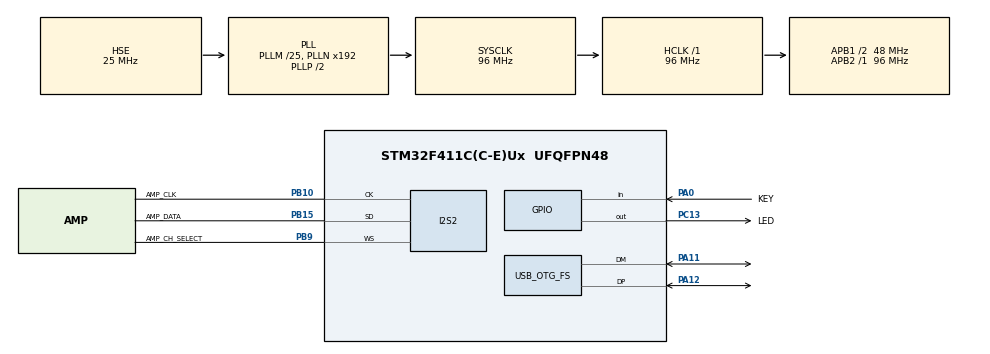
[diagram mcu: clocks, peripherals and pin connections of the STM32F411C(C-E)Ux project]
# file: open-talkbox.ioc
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Dma.Request0=SPI2_TX
Dma.SPI2_TX.0.Direction=DMA_MEMORY_TO_PERIPH
Dma.SPI2_TX.0.FIFOMode=DMA_FIFOMODE_DISABLE
Dma.SPI2_TX.0.Instance=DMA1_Stream4
Dma.SPI2_TX.0.MemDataAlignment=DMA_MDATAALIGN_HALFWORD
Dma.SPI2_TX.0.MemInc=DMA_MINC_ENABLE
Dma.SPI2_TX.0.Mode=DMA_CIRCULAR
Dma.SPI2_TX.0.PeriphDataAlignment=DMA_PDATAALIGN_HALFWORD
Dma.SPI2_TX.0.PeriphInc=DMA_PINC_DISABLE
Dma.SPI2_TX.0.Priority=DMA_PRIORITY_LOW
I2S2.AudioFreq=I2S_AUDIOFREQ_16K
I2S2.ErrorAudioFreq=-0.12 %
I2S2.FullDuplexMode=I2S_FULLDUPLEXMODE_DISABLE
I2S2.Instance=SPI$Index
I2S2.RealAudioFreq=15.98 KHz
I2S2.VirtualMode=I2S_MODE_MASTER
Mcu.Family=STM32F4
Mcu.Name=STM32F411C(C-E)Ux
Mcu.Package=UFQFPN48
NVIC.DMA1_Stream4_IRQn=true\:0\:0\:false\:false\:true\:false\:true
NVIC.OTG_FS_IRQn=true\:0\:0\:false\:false\:true\:false\:true
NVIC.PriorityGroup=NVIC_PRIORITYGROUP_4
PA0-WKUP.GPIO_Label=KEY
PA0-WKUP.GPIO_PuPd=GPIO_PULLUP
PA0-WKUP.Signal=GPIO_Input
PA11.Mode=Device_Only
PA11.Signal=USB_OTG_FS_DM
PA12.Mode=Device_Only
PA12.Signal=USB_OTG_FS_DP
PA13.Mode=Serial_Wire
PA13.Signal=SYS_JTMS-SWDIO
PA14.Mode=Serial_Wire
PA14.Signal=SYS_JTCK-SWCLK
PB10.GPIO_Label=AMP_CLK
PB10.Mode=Half_Duplex_Master
PB10.Signal=I2S2_CK
PB15.GPIO_Label=AMP_DATA
PB15.Mode=Half_Duplex_Master
PB15.Signal=I2S2_SD
PB9.GPIO_Label=AMP_CH_SELECT
PB9.Mode=Half_Duplex_Master
PB9.Signal=I2S2_WS
PC13-ANTI_TAMP.GPIO_Label=LED
PC13-ANTI_TAMP.Signal=GPIO_Output
PC14-OSC32_IN.Mode=LSE-External-Oscillator
PC14-OSC32_IN.Signal=RCC_OSC32_IN
PC15-OSC32_OUT.Mode=LSE-External-Oscillator
PC15-OSC32_OUT.Signal=RCC_OSC32_OUT
PH0\ -\ OSC_IN.Mode=HSE-External-Oscillator
PH0\ -\ OSC_IN.Signal=RCC_OSC_IN
PH1\ -\ OSC_OUT.Mode=HSE-External-Oscillator
PH1\ -\ OSC_OUT.Signal=RCC_OSC_OUT
ProjectManager.HeapSize=0x200
ProjectManager.StackSize=0x400
ProjectManager.TargetToolchain=STM32CubeIDE
RCC.48MHZClocksFreq_Value=48000000
RCC.AHBFreq_Value=96000000
RCC.APB1CLKDivider=RCC_HCLK_DIV2
RCC.APB1Freq_Value=48000000
RCC.APB1TimFreq_Value=96000000
RCC.APB2Freq_Value=96000000
RCC.APB2TimFreq_Value=96000000
RCC.CortexFreq_Value=96000000
RCC.HCLKFreq_Value=96000000
RCC.HSE_VALUE=25000000
RCC.HSI_VALUE=16000000
RCC.PLLI2SM=25
RCC.PLLI2SN=180
RCC.PLLI2SR=4
RCC.PLLM=25
RCC.SYSCLKFreq_VALUE=96000000
RCC.SYSCLKSource=RCC_SYSCLKSOURCE_PLLCLK
RCC.VCOOutputFreq_Value=192000000
USB_DEVICE.CLASS_NAME_FS=AUDIO
USB_DEVICE.VirtualMode=Audio
USB_DEVICE.VirtualModeFS=Audio_FS
USB_OTG_FS.VirtualMode=Device_Only
VP_USB_DEVICE_VS_USB_DEVICE_AUDIO_FS.Mode=AUDIO_FS
board=custom

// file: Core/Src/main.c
/* USER CODE BEGIN Header */
/**
  ******************************************************************************
  * @file           : main.c
  * @brief          : Main program body
  ******************************************************************************
  * @attention
  *
  * <h2><center>&copy; Copyright (c) 2020 STMicroelectronics.
  * All rights reserved.</center></h2>
  *
  * This software component is licensed by ST under BSD 3-Clause license,
  * the "License"; You may not use this file except in compliance with the
  * License. You may obtain a copy of the License at:
  *                        opensource.org/licenses/BSD-3-Clause
  *
  ******************************************************************************
  */
/* USER CODE END Header */

#include "main.h"
#include "dma.h"
#include "i2s.h"
#include "usb_device.h"
#include "gpio.h"

/* USER CODE BEGIN Includes */
#include "program.h"
/* USER CODE END Includes */

void SystemClock_Config(void);

int main(void)
{

  /* MCU Configuration--------------------------------------------------------*/

  /* Reset of all peripherals, Initializes the Flash interface and the Systick. */
  HAL_Init();

  /* Configure the system clock */
  SystemClock_Config();

  /* Initialize all configured peripherals */
  MX_GPIO_Init();
  MX_USB_DEVICE_Init();
  MX_DMA_Init();
  MX_I2S2_Init();
  /* USER CODE BEGIN 2 */
  entrypoint();
  /* USER CODE END 2 */

  /* Infinite loop */
  while (1)
  {

  }
}

void SystemClock_Config(void)
{
  RCC_OscInitTypeDef RCC_OscInitStruct = {0};
  RCC_ClkInitTypeDef RCC_ClkInitStruct = {0};
  RCC_PeriphCLKInitTypeDef PeriphClkInitStruct = {0};

  /** Configure the main internal regulator output voltage
  */
  __HAL_RCC_PWR_CLK_ENABLE();
  __HAL_PWR_VOLTAGESCALING_CONFIG(PWR_REGULATOR_VOLTAGE_SCALE1);
  /** Initializes the CPU, AHB and APB busses clocks
  */
  RCC_OscInitStruct.OscillatorType = RCC_OSCILLATORTYPE_HSE;
  RCC_OscInitStruct.HSEState = RCC_HSE_ON;
  RCC_OscInitStruct.PLL.PLLState = RCC_PLL_ON;
  RCC_OscInitStruct.PLL.PLLSource = RCC_PLLSOURCE_HSE;
  RCC_OscInitStruct.PLL.PLLM = 25;
  RCC_OscInitStruct.PLL.PLLN = 192;
  RCC_OscInitStruct.PLL.PLLP = RCC_PLLP_DIV2;
  RCC_OscInitStruct.PLL.PLLQ = 4;
  if (HAL_RCC_OscConfig(&RCC_OscInitStruct) != HAL_OK)
  {
    Error_Handler();
  }
  /** Initializes the CPU, AHB and APB busses clocks
  */
  RCC_ClkInitStruct.ClockType = RCC_CLOCKTYPE_HCLK|RCC_CLOCKTYPE_SYSCLK
                              |RCC_CLOCKTYPE_PCLK1|RCC_CLOCKTYPE_PCLK2;
  RCC_ClkInitStruct.SYSCLKSource = RCC_SYSCLKSOURCE_PLLCLK;
  RCC_ClkInitStruct.AHBCLKDivider = RCC_SYSCLK_DIV1;
  RCC_ClkInitStruct.APB1CLKDivider = RCC_HCLK_DIV2;
  RCC_ClkInitStruct.APB2CLKDivider = RCC_HCLK_DIV1;

  if (HAL_RCC_ClockConfig(&RCC_ClkInitStruct, FLASH_LATENCY_3) != HAL_OK)
  {
    Error_Handler();
  }
  PeriphClkInitStruct.PeriphClockSelection = RCC_PERIPHCLK_I2S;
  PeriphClkInitStruct.PLLI2S.PLLI2SN = 180;
  PeriphClkInitStruct.PLLI2S.PLLI2SM = 25;
  PeriphClkInitStruct.PLLI2S.PLLI2SR = 4;
  if (HAL_RCCEx_PeriphCLKConfig(&PeriphClkInitStruct) != HAL_OK)
  {
    Error_Handler();
  }
}

void Error_Handler(void)
{
}

/************************ (C) COPYRIGHT STMicroelectronics *****END OF FILE****/
